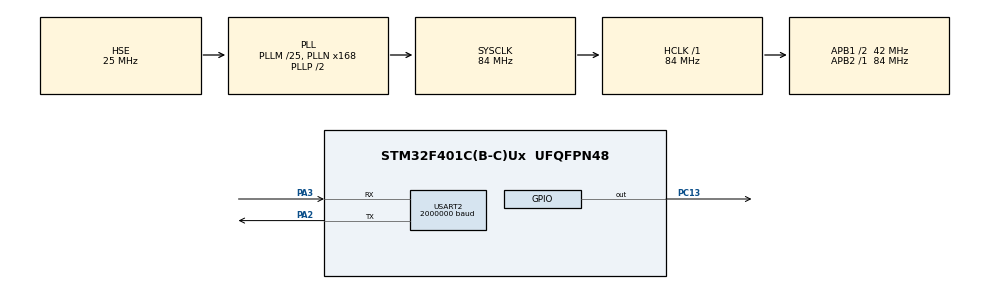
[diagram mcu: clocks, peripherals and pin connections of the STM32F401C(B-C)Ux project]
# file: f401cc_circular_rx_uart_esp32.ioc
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Mcu.Family=STM32F4
RCC.PLLSourceVirtual=RCC_PLLSOURCE_HSE
Dma.USART2_TX.1.Priority=DMA_PRIORITY_LOW
RCC.CortexFreq_Value=84000000
Dma.USART2_TX.1.FIFOMode=DMA_FIFOMODE_DISABLE
Dma.USART2_TX.1.MemInc=DMA_MINC_ENABLE
PH1\ -\ OSC_OUT.Mode=HSE-External-Oscillator
Dma.USART2_RX.0.Direction=DMA_PERIPH_TO_MEMORY
RCC.APB1CLKDivider=RCC_HCLK_DIV2
Dma.USART2_TX.1.PeriphDataAlignment=DMA_PDATAALIGN_BYTE
USART2.BaudRate=2000000
RCC.SYSCLKSource=RCC_SYSCLKSOURCE_PLLCLK
ProjectManager.StackSize=0x400
Dma.USART2_RX.0.Mode=DMA_CIRCULAR
PA13.Signal=SYS_JTMS-SWDIO
PA3.Mode=Asynchronous
PH0\ -\ OSC_IN.Mode=HSE-External-Oscillator
PH0\ -\ OSC_IN.Signal=RCC_OSC_IN
ProjectManager.TargetToolchain=STM32CubeIDE
NVIC.DMA1_Stream5_IRQn=true\:0\:0\:false\:false\:true\:false\:true
Dma.USART2_RX.0.Priority=DMA_PRIORITY_MEDIUM
Dma.USART2_RX.0.PeriphDataAlignment=DMA_PDATAALIGN_BYTE
RCC.HCLKFreq_Value=84000000
RCC.APB2TimFreq_Value=84000000
Dma.USART2_TX.1.Mode=DMA_CIRCULAR
RCC.LSE_VALUE=32768
RCC.AHBFreq_Value=84000000
RCC.HSE_VALUE=25000000
PH1\ -\ OSC_OUT.Signal=RCC_OSC_OUT
Dma.USART2_TX.1.PeriphInc=DMA_PINC_DISABLE
board=custom
PC13-ANTI_TAMP.Signal=GPIO_Output
RCC.VCOOutputFreq_Value=168000000
Dma.USART2_TX.1.Direction=DMA_MEMORY_TO_PERIPH
RCC.APB2Freq_Value=84000000
Dma.USART2_RX.0.MemDataAlignment=DMA_MDATAALIGN_BYTE
PA14.Mode=Serial_Wire
Dma.USART2_TX.1.Instance=DMA1_Stream6
Dma.USART2_RX.0.Instance=DMA1_Stream5
PA13.Mode=Serial_Wire
Mcu.Name=STM32F401C(B-C)Ux
Dma.USART2_RX.0.MemInc=DMA_MINC_ENABLE
PA2.Signal=USART2_TX
RCC.48MHZClocksFreq_Value=42000000
RCC.SYSCLKFreq_VALUE=84000000
Mcu.Package=UFQFPN48
Dma.USART2_RX.0.PeriphInc=DMA_PINC_DISABLE
USART2.VirtualMode=VM_ASYNC
Dma.USART2_RX.0.FIFOMode=DMA_FIFOMODE_DISABLE
PA14.Signal=SYS_JTCK-SWCLK
ProjectManager.HeapSize=0x200
RCC.HSI_VALUE=16000000
NVIC.PriorityGroup=NVIC_PRIORITYGROUP_4
RCC.PLLM=25
RCC.PLLN=168
Dma.Request1=USART2_TX
RCC.APB1TimFreq_Value=84000000
PA2.Mode=Asynchronous
Dma.USART2_TX.1.MemDataAlignment=DMA_MDATAALIGN_BYTE
RCC.APB1Freq_Value=42000000
NVIC.DMA1_Stream6_IRQn=true\:0\:0\:false\:false\:true\:false\:true
Dma.Request0=USART2_RX
USART2.Mode=MODE_TX_RX
PA3.Signal=USART2_RX

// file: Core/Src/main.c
/* USER CODE BEGIN Header */
/**
  ******************************************************************************
  * @file           : main.c
  * @brief          : Main program body
  ******************************************************************************
  * @attention
  *
  * <h2><center>&copy; Copyright (c) 2023 STMicroelectronics.
  * All rights reserved.</center></h2>
  *
  * This software component is licensed by ST under BSD 3-Clause license,
  * the "License"; You may not use this file except in compliance with the
  * License. You may obtain a copy of the License at:
  *                        opensource.org/licenses/BSD-3-Clause
  *
  ******************************************************************************
  */
/* USER CODE END Header */
#include "main.h"

UART_HandleTypeDef huart2;
DMA_HandleTypeDef hdma_usart2_rx;
DMA_HandleTypeDef hdma_usart2_tx;

/* USER CODE BEGIN PV */
uint8_t tx = 6;
uint8_t rx[24],rxadd;

/* USER CODE END PV */

void SystemClock_Config(void);
static void MX_GPIO_Init(void);
static void MX_DMA_Init(void);
static void MX_USART2_UART_Init(void);
/* USER CODE BEGIN PFP */
//void HAL_UART_ErrorCallback(UART_HandleTypeDef *huart2);
/* USER CODE END PFP */

int main(void)
{

  /* MCU Configuration--------------------------------------------------------*/

  /* Reset of all peripherals, Initializes the Flash interface and the Systick. */
  HAL_Init();

  /* Configure the system clock */
  SystemClock_Config();

  /* Initialize all configured peripherals */
  MX_GPIO_Init();
  MX_DMA_Init();
  MX_USART2_UART_Init();
  /* USER CODE BEGIN 2 */
  if(HAL_UART_Transmit_DMA(&huart2, &tx, sizeof(tx))!=HAL_OK){
	  while(1);
  }
  HAL_UART_Receive_DMA(&huart2, rx, sizeof(rx));
  HAL_Delay(1000);
  /* USER CODE END 2 */

  /* Infinite loop */
  /* USER CODE BEGIN WHILE */
  while (1){

	  while(rx[0]!=55 && rx[1]!=66 && rx[2]!=88){   /// mengecek data header 55 66 88 jika benar maka menerima data jika tidak maka stm32 melakukan reset terus menerus
		  NVIC_SystemReset();
		  HAL_GPIO_WritePin(GPIOC, GPIO_PIN_13, GPIO_PIN_SET);
	  }
HAL_GPIO_WritePin(GPIOC, GPIO_PIN_13, GPIO_PIN_RESET);

//  while(1){
//	HAL_UART_Receive(&huart2, &rxadd, sizeof(rxadd), 1);
//	if(rxadd==1){
//		HAL_UART_Transmit(&huart2, &tx, sizeof(tx), 0);
//		break;
//	}
//}
//  HAL_UART_Receive(&huart2, rx, sizeof(rx), 1);
	  //HAL_Delay(10);
    /* USER CODE END WHILE */

  }
}

void SystemClock_Config(void)
{
  RCC_OscInitTypeDef RCC_OscInitStruct = {0};
  RCC_ClkInitTypeDef RCC_ClkInitStruct = {0};

  /** Configure the main internal regulator output voltage
  */
  __HAL_RCC_PWR_CLK_ENABLE();
  __HAL_PWR_VOLTAGESCALING_CONFIG(PWR_REGULATOR_VOLTAGE_SCALE2);
  /** Initializes the RCC Oscillators according to the specified parameters
  * in the RCC_OscInitTypeDef structure.
  */
  RCC_OscInitStruct.OscillatorType = RCC_OSCILLATORTYPE_HSE;
  RCC_OscInitStruct.HSEState = RCC_HSE_ON;
  RCC_OscInitStruct.PLL.PLLState = RCC_PLL_ON;
  RCC_OscInitStruct.PLL.PLLSource = RCC_PLLSOURCE_HSE;
  RCC_OscInitStruct.PLL.PLLM = 25;
  RCC_OscInitStruct.PLL.PLLN = 168;
  RCC_OscInitStruct.PLL.PLLP = RCC_PLLP_DIV2;
  RCC_OscInitStruct.PLL.PLLQ = 4;
  if (HAL_RCC_OscConfig(&RCC_OscInitStruct) != HAL_OK)
  {
    Error_Handler();
  }
  /** Initializes the CPU, AHB and APB buses clocks
  */
  RCC_ClkInitStruct.ClockType = RCC_CLOCKTYPE_HCLK|RCC_CLOCKTYPE_SYSCLK
                              |RCC_CLOCKTYPE_PCLK1|RCC_CLOCKTYPE_PCLK2;
  RCC_ClkInitStruct.SYSCLKSource = RCC_SYSCLKSOURCE_PLLCLK;
  RCC_ClkInitStruct.AHBCLKDivider = RCC_SYSCLK_DIV1;
  RCC_ClkInitStruct.APB1CLKDivider = RCC_HCLK_DIV2;
  RCC_ClkInitStruct.APB2CLKDivider = RCC_HCLK_DIV1;

  if (HAL_RCC_ClockConfig(&RCC_ClkInitStruct, FLASH_LATENCY_2) != HAL_OK)
  {
    Error_Handler();
  }
}

static void MX_USART2_UART_Init(void)
{

  huart2.Instance = USART2;
  huart2.Init.BaudRate = 2000000;
  huart2.Init.WordLength = UART_WORDLENGTH_8B;
  huart2.Init.StopBits = UART_STOPBITS_1;
  huart2.Init.Parity = UART_PARITY_NONE;
  huart2.Init.Mode = UART_MODE_TX_RX;
  huart2.Init.HwFlowCtl = UART_HWCONTROL_NONE;
  huart2.Init.OverSampling = UART_OVERSAMPLING_16;
  if (HAL_UART_Init(&huart2) != HAL_OK)
  {
    Error_Handler();
  }

}

static void MX_DMA_Init(void)
{

  /* DMA controller clock enable */
  __HAL_RCC_DMA1_CLK_ENABLE();

  /* DMA interrupt init */
  /* DMA1_Stream5_IRQn interrupt configuration */
  HAL_NVIC_SetPriority(DMA1_Stream5_IRQn, 0, 0);
  HAL_NVIC_EnableIRQ(DMA1_Stream5_IRQn);
  /* DMA1_Stream6_IRQn interrupt configuration */
  HAL_NVIC_SetPriority(DMA1_Stream6_IRQn, 0, 0);
  HAL_NVIC_EnableIRQ(DMA1_Stream6_IRQn);

}

static void MX_GPIO_Init(void)
{
  GPIO_InitTypeDef GPIO_InitStruct = {0};

  /* GPIO Ports Clock Enable */
  __HAL_RCC_GPIOC_CLK_ENABLE();
  __HAL_RCC_GPIOH_CLK_ENABLE();
  __HAL_RCC_GPIOA_CLK_ENABLE();

  /*Configure GPIO pin Output Level */
  HAL_GPIO_WritePin(GPIOC, GPIO_PIN_13, GPIO_PIN_RESET);

  /*Configure GPIO pin : PC13 */
  GPIO_InitStruct.Pin = GPIO_PIN_13;
  GPIO_InitStruct.Mode = GPIO_MODE_OUTPUT_PP;
  GPIO_InitStruct.Pull = GPIO_NOPULL;
  GPIO_InitStruct.Speed = GPIO_SPEED_FREQ_LOW;
  HAL_GPIO_Init(GPIOC, &GPIO_InitStruct);

}

/* USER CODE BEGIN 4 */
//void HAL_UART_ErrorCallback(UART_HandleTypeDef *huart2){
//	HAL_UART_DeInit(huart2);
////	  if(HAL_UART_Transmit_DMA(&huart2, &tx, sizeof(tx))!=HAL_OK){
////		  while(1);
////	  }
//	  HAL_UART_Receive_DMA(huart2, rx, sizeof(rx));
//}
/* USER CODE END 4 */

void Error_Handler(void)
{
  __disable_irq();
  while (1)
  {
  }
}

/************************ (C) COPYRIGHT STMicroelectronics *****END OF FILE****/
